# myChip register map
Vendor: ARM Ltd.; Series: ARMCM3; File version: 1.2
CPU: CM3 r2p1, little endian, no MPU, no FPU, 3 interrupt priority bits
Registers are 32-bit, read-write, reset 0x0 unless marked. A register's access mark holds for its fields unless they carry their own. Offsets are from the block's base; [hi:lo] are bit positions.

## UART0
Base 0x40003000
Same registers: UART1 0x40004000, UART2 0x40005000, UART3 0x40010000, UART4 0x40011000
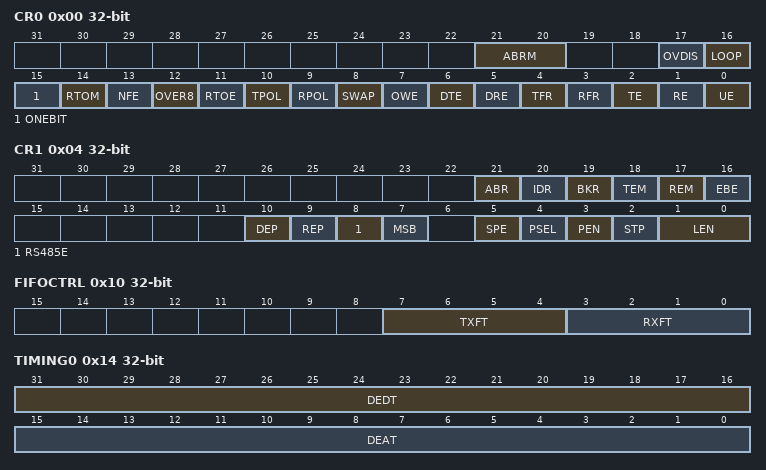
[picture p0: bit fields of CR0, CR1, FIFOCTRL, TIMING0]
0x00 CR0 — UART Control Register0
  [21:20] ABRM — UART自动波特率检测模式（UART Auto Baud Rate Mode）
  [17] OVDIS — UART RX-OVERDIS模式使能 (UART RX OVERDIS Enable)
  [16] LOOP — UART LOOPBACK模式选择 (UART LOOPBACK Mode Select)
  [15] ONEBIT — UART ONEBIT模式选择 (UART ONEBIT Mode Select)
  [14] RTOM — UART RTO模式选择 (UART RTO Mode Select)
  [13] NFE — UART非FIFO模式使能 (UART Non-FIFO Mode Enable)
  [12] OVER8 — UART过采样模式选择 (UART Oversampling Mode Select)
  [11] RTOE — UART RX超时使能（UART RX Timeout Enable）
  [10] TPOL — UART TX引脚极性选择（UART TX Polarity Select）
  [9] RPOL — UART RX引脚极性选择（UART RX Polarity Select）
  [8] SWAP — UART TX和RX引脚交换使能（UART TX/RX Swap Enable）
  [7] OWE — UART单线模式使能（UART One-Wire Enable）
  [6] DTE — UART TX-DMA使能（UART TX DMA Enable）
  [5] DRE — UART RX-DMA使能（UART RX DMA Enable）
  [4] TFR — UART TX-FIFO复位（UART TX-FIFO Reset）
  [3] RFR — UART RX-FIFO复位（UART RX-FIFO Reset）
  [2] TE — UART TX使能（UART TX Enable）
  [1] RE — UART RX使能（UART RX Enable）
  [0] UE — UART使能（UART Enable）
0x04 CR1 — UART Control Register1
  [21] ABR — UART自动波特率检测使能（UART Auto Baud Rate Enable）
  [20] IDR — UART IDLE帧请求位（UART IDLE Request）
  [19] BKR — UART Break帧请求位（UART Break Request）
  [18] TEM — UART TX拓展模式选择（UART TX Extend-Mode Select）
  [17] REM — UART RX拓展模式选择（UART RX Extend-Mode Select）
  [16] EBE — UART拓展位使能（UART Extend-Bit Enable）
  [10] DEP — UART DE极性（UART DE Polarity）
  [9] REP — UART RE极性（UART RE Polarity）
  [8] RS485E — UART RS485 功能使能（UART RS485 Enable）
  [7] MSB — UART MSB使能（UART MSB Enable）
  [5] SPE — UART强制校验使能位（UART Stick Parity Enable）
  [4] PSEL — UART奇偶检验选择（UART Parity Select）
  [3] PEN — UART奇偶检验位使能（UART Parity Enable）
  [2] STP — UART Stop位选择（UART Stop Select）
  [1:0] LEN — UART数据长度选择（UART Length Select）
0x08 BAUD — UART Baud Rate Register
  [15:0] BAUD — UART波特率配置（UART Baud Rate）
0x10 FIFOCTRL — UART FIFO Control Register
  [7:4] TXFT — UART TXFIFO空中断阈值（UART TXFIFO Level-Empty Threshold）
  [3:0] RXFT — UART RXFIFO满中断阈值（UART RX-FIFO Level-Full Threshold）
0x14 TIMING0 — UART Timing Register0
  [31:16] DEDT — UART DE驱动禁止时间（UART DE Deassertion Timing）
  [15:0] DEAT — UART DE驱动使能时间（UART DE Assertion Timing）
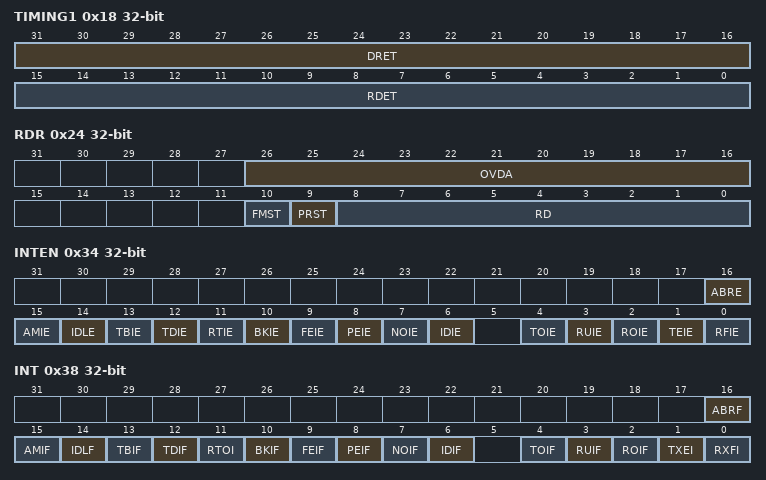
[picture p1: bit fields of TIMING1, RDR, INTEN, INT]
0x18 TIMING1 — UART Timing Register1
  [31:16] DRET — UART DE到RE切换时间（UART DE2RE Turn-Around Timing）
  [15:0] RDET — UART RE到DE切换时间（UART RE2DE Turn-Around Timing）
0x20 TDR — UART Transmit Data Register
  [8:0] TD — UART TX数据寄存器（UART Transmit Data Register）
0x24 RDR — UART Receive Data Register
  [26:16] OVDA — UART RX上溢数据寄存器（UART RX OVER DATA）
  [10] FMST ro — UART RX帧状态（UART RX Frame Status）
  [9] PRST ro — UART RX奇偶校验位状态（UART RX Parity Status）
  [8:0] RD ro — UART RX数据寄存器（UART Receive Data Register）
0x28 TAR — UART Transmit Address Register
  [7:0] TAR — UART TX发送地址寄存器（UART Transmit Address Register）
0x2C RAR — UART Receive Address Register
  [7:0] RAR — UART RX接收地址寄存器（UART Receive Address Register）
0x30 RTO — UART Receiver Timeout Register
  [15:0] RTO — UART RX超时阈值（Receiver Timeout Timing）
0x34 INTEN — UART Interrupt Enable Register
  [16] ABRE — UART 自动波特率检测错误中断使能（UART Auto Baud Rate Error Interrupt Enable）
  [15] AMIE — UART RX地址匹配中断使能（UART RX Address Match Interrupt Enable）
  [14] IDLE — UART TX Idle完成中断使能（UART TX Idle Done Interrupt Enable）
  [13] TBIE — UART TX Break完成中断使能（UART TX Break Done Interrupt Enable）
  [12] TDIE — UART TX传输完成中断使能（UART TX Done Interrupt Enable）
  [11] RTIE — UART RX传输超时中断使能（UART RX Timeout Interrupt Enable）
  [10] BKIE — UART RX Break中断使能（UART RX Break Interrupt Enable）
  [9] FEIE — UART RX传输帧错误中断使能（UART Frame Error Interrupt Enable）
  [8] PEIE — UART RX奇偶校验错误中断使能（UART Parity Error Interrupt Enable）
  [7] NOIE — UART 噪声检测中断使能（UART Noise Detection Interrupt Enable）
  [6] IDIE — UART 空闲中断使能（UART Idle Interrupt Enable）
  [4] TOIE — UART TX-FIFO上溢中断使能（UART TX-FIFO Overflow Interrupt Enable）
  [3] RUIE — UART RX-FIFO下溢中断使能（UART RX-FIFO Underflow Interrupt Enable）
  [2] ROIE — UART RX-FIFO上溢中断使能（UART RX-FIFO Overflow Interrupt Enable）
  [1] TEIE — UART TX-FIFO空中断使能（UART TX-FIFO Empty Interrupt Enable）
  [0] RFIE — UART RX-FIFO满中断使能（UART RX-FIFO Full Interrupt Enable）
0x38 INT — UART Interrupt Register
  [16] ABRF — UART 自动波特率检测错误中断标志（UART Auto Baud Rate Error Interrupt Flag）
  [15] AMIF — UART RX地址匹配中断标志（UART RX Address Match Interrupt Flag）
  [14] IDLF — UART TX Idle完成中断标志（UART TX Idle Done Interrupt Flag）
  [13] TBIF — UART TX Break完成中断标志（UART TX Break Done Interrupt Flag）
  [12] TDIF — UART发送完成中断标志（UART TX Done Interrupt Flag）
  [11] RTOI — UART RX传输超时中断标志（UART RX Timeout Interrupt Flag）
  [10] BKIF — UART RX BREAK中断标志（UART Break Interrupt Flag）
  [9] FEIF — UART RX帧错误中断标志（UART Frame Error Interrupt Flag）
  [8] PEIF — UART奇偶校验错误中断标志（UART Parity Error Interrupt Flag）
  [7] NOIF — UART 噪声检测中断标志（UART Noise Detection Interrupt Flag）
  [6] IDIF — UART空闲中断标志（UART Idle Interrupt Flag）
  [4] TOIF — UART TX-FIFO上溢错误中断标志（UART TX-FIFO Overflow Interrupt Flag）
  [3] RUIF — UART RX-FIFO下溢中断标志（UART RX-FIFO Underflow Interrupt Flag）
  [2] ROIF — UART RX-FIFO上溢中断标志（UART RX-FIFO Overflow Interrupt Flag）
  [1] TXEI ro — UART TX-FIFO阈值空中断标志（UART TX-FIFO Level-Empty Interrupt Flag）
  [0] RXFI ro — UART RX-FIFO阈值满中断标志（UART RX-FIFO Level-Full Interrupt Flag）
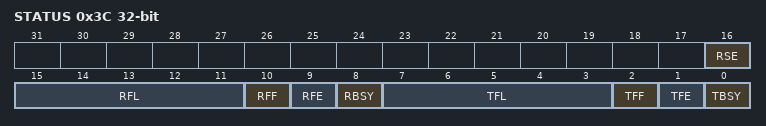
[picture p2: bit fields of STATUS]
0x3C STATUS — UART Status Register
  [16] RSE ro — UART RX-Start错误标志位（UART RX-Start Error Flag）
  [15:11] RFL ro — UART RX-FIFO实时剩余数据量（UART RX-FIFO Level Register）
  [10] RFF ro — UART RX接收FIFO满标志（UART RX-FIFO Full Flag）
  [9] RFE ro — UART RX接收FIFO空标志（UART RX-FIFO Empty Flag）
  [8] RBSY ro — UART RX总线忙碌标志（UART RX Busy Flag）
  [7:3] TFL ro — UART TX-FIFO实时剩余数据量（UART TX-FIFO Level Register）
  [2] TFF ro — UART TX发送FIFO满标志（UART TX-FIFO Full Flag）
  [1] TFE ro — UART TX发送FIFO空标志（UART TX-FIFO Empty Flag）
  [0] TBSY ro — UART TX总线忙碌标志（UART TX Busy Flag）
